# STM32L100 register map
File version: 1.3
CPU: CM3 r1p1, little endian, no MPU, no FPU, 4 interrupt priority bits
Registers are 32-bit, read-write, reset 0x0 unless marked. A register's access mark holds for its fields unless they carry their own. Offsets are from the block's base; [hi:lo] are bit positions; {n}, {i} and the like mark numbered series.

## IWDG — Independent watchdog
Base 0x40003000
0x00 KR wo — Key register
  [15:0] KEY — Key value (write only, read 0000h)
0x04 PR — Prescaler register
  [2:0] PR — Prescaler divider
0x08 RLR reset 0xFFF — Reload register
  [11:0] RL — Watchdog counter reload value
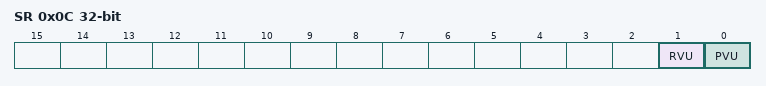
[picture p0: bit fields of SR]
0x0C SR ro — Status register
  [1] RVU — Watchdog counter reload value update
  [0] PVU — Watchdog prescaler value update

## LCD — Liquid crystal display controller
Base 0x40002400
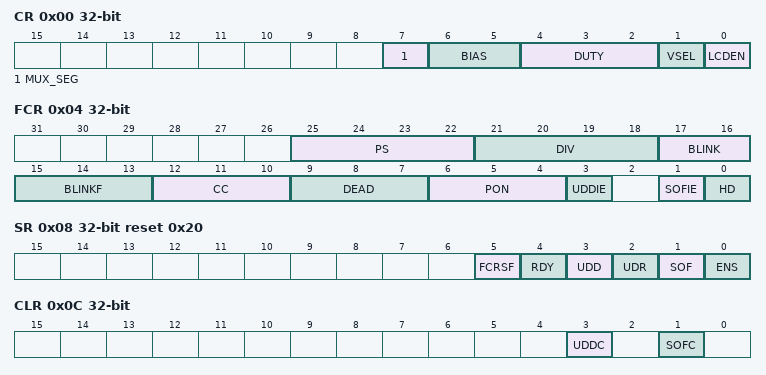
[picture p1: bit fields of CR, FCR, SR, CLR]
0x00 CR — control register
  [7] MUX_SEG — Mux segment enable
  [6:5] BIAS — Bias selector
  [4:2] DUTY — Duty selection
  [1] VSEL — Voltage source selection
  [0] LCDEN — LCD controller enable
0x04 FCR — frame control register
  [25:22] PS — PS 16-bit prescaler
  [21:18] DIV — DIV clock divider
  [17:16] BLINK — Blink mode selection
  [15:13] BLINKF — Blink frequency selection
  [12:10] CC — Contrast control
  [9:7] DEAD — Dead time duration
  [6:4] PON — Pulse ON duration
  [3] UDDIE — Update display done interrupt enable
  [1] SOFIE — Start of frame interrupt enable
  [0] HD — High drive enable
0x08 SR access per field reset 0x20 — status register
  [5] FCRSF ro — LCD Frame Control Register Synchronization flag
  [4] RDY ro — Ready flag
  [3] UDD ro — Update Display Done
  [2] UDR rw — Update display request
  [1] SOF ro — Start of frame flag
  [0] ENS ro — LCD enabled status
0x0C CLR wo — clear register
  [3] UDDC — Update display done clear
  [1] SOFC — Start of frame flag clear
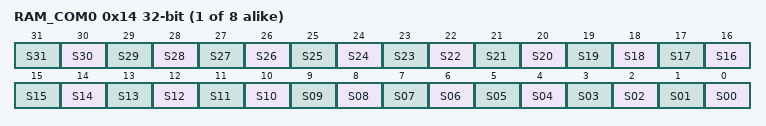
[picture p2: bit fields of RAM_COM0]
{0x14+8i} RAM_COM{i} (i=0..7) — display memory
  [n] S{n:02} (n=0..31)

## OPAMP — Operational amplifiers
Base 0x40007C5C
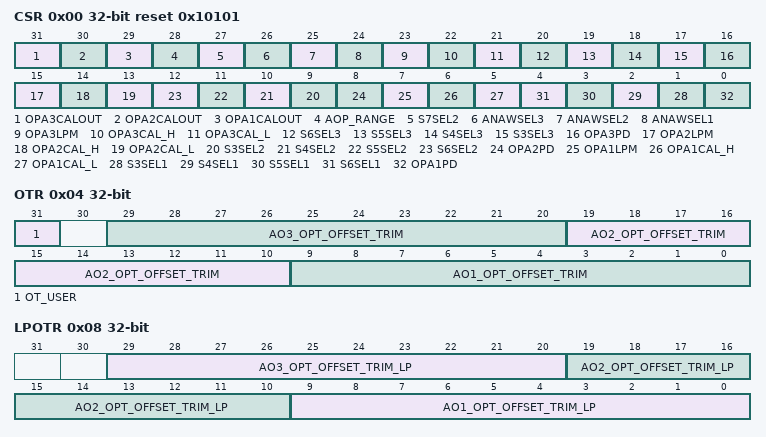
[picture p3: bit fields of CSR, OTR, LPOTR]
0x00 CSR reset 0x10101 — control/status register
  [31] OPA3CALOUT — OPAMP3 calibration output
  [30] OPA2CALOUT — OPAMP2 calibration output
  [29] OPA1CALOUT — OPAMP1 calibration output
  [28] AOP_RANGE — Power range selection
  [27] S7SEL2 — Switch 7 for OPAMP2 enable
  [26] ANAWSEL3 — Switch SanA enable for OPAMP3
  [25] ANAWSEL2 — Switch SanA enable for OPAMP2
  [24] ANAWSEL1 — Switch SanA enable for OPAMP1
  [23] OPA3LPM — OPAMP3 low power mode
  [22] OPA3CAL_H — OPAMP3 offset calibration for N differential pair
  [21] OPA3CAL_L — OPAMP3 offset Calibration for P differential pair
  [20] S6SEL3 — Switch 6 for OPAMP3 enable
  [19] S5SEL3 — Switch 5 for OPAMP3 enable
  [18] S4SEL3 — Switch 4 for OPAMP3 enable
  [17] S3SEL3 — Switch 3 for OPAMP3 Enable
  [16] OPA3PD — OPAMP3 power down
  [15] OPA2LPM — OPAMP2 low power mode
  [14] OPA2CAL_H — OPAMP2 offset calibration for N differential pair
  [13] OPA2CAL_L — OPAMP2 offset Calibration for P differential pair
  [n+6] S{n}SEL2 (n=3..6) — Switch {n} for OPAMP2 enable
  [8] OPA2PD — OPAMP2 power down
  [7] OPA1LPM — OPAMP1 low power mode
  [6] OPA1CAL_H — OPAMP1 offset calibration for N differential pair
  [5] OPA1CAL_L — OPAMP1 offset calibration for P differential pair
  [n-2] S{n}SEL1 (n=3..6) — Switch {n} for OPAMP1 enable
  [0] OPA1PD — OPAMP1 power down
0x04 OTR — offset trimming register for normal mode
  [31] OT_USER — Select user or factory trimming value
  [29:20] AO3_OPT_OFFSET_TRIM — OPAMP3, 10-bit offset trim value for normal mode
  [19:10] AO2_OPT_OFFSET_TRIM — OPAMP2, 10-bit offset trim value for normal mode
  [9:0] AO1_OPT_OFFSET_TRIM — OPAMP1, 10-bit offset trim value for normal mode
0x08 LPOTR — OPAMP offset trimming register for low power mode
  [29:20] AO3_OPT_OFFSET_TRIM_LP — OPAMP3, 10-bit offset trim value for low power mode
  [19:10] AO2_OPT_OFFSET_TRIM_LP — OPAMP2, 10-bit offset trim value for low power mode
  [9:0] AO1_OPT_OFFSET_TRIM_LP — OPAMP1, 10-bit offset trim value for low power mode

## PWR — Power control
Base 0x40007000
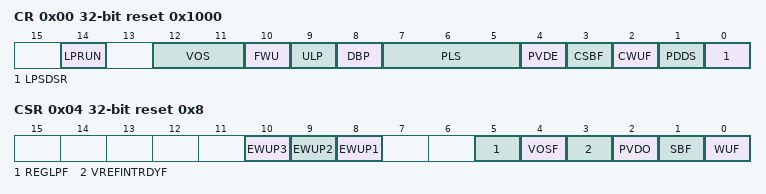
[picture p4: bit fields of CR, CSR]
0x00 CR reset 0x1000 — power control register
  [14] LPRUN — Low power run mode
  [12:11] VOS — Voltage scaling range selection
  [10] FWU — Fast wakeup
  [9] ULP — Ultralow power mode
  [8] DBP — Disable backup domain write protection
  [7:5] PLS — PVD level selection
  [4] PVDE — Power voltage detector enable
  [3] CSBF — Clear standby flag
  [2] CWUF — Clear wakeup flag
  [1] PDDS — Power down deepsleep
  [0] LPSDSR — Low-power deep sleep
0x04 CSR access per field reset 0x8 — power control/status register
  [10] EWUP3 rw — Enable WKUP pin 3
  [9] EWUP2 rw — Enable WKUP pin 2
  [8] EWUP1 rw — Enable WKUP pin 1
  [5] REGLPF ro — Regulator LP flag
  [4] VOSF ro — Voltage Scaling select flag
  [3] VREFINTRDYF ro — Internal voltage reference (VREFINT) ready flag
  [2] PVDO ro — PVD output
  [1] SBF ro — Standby flag
  [0] WUF ro — Wakeup flag
